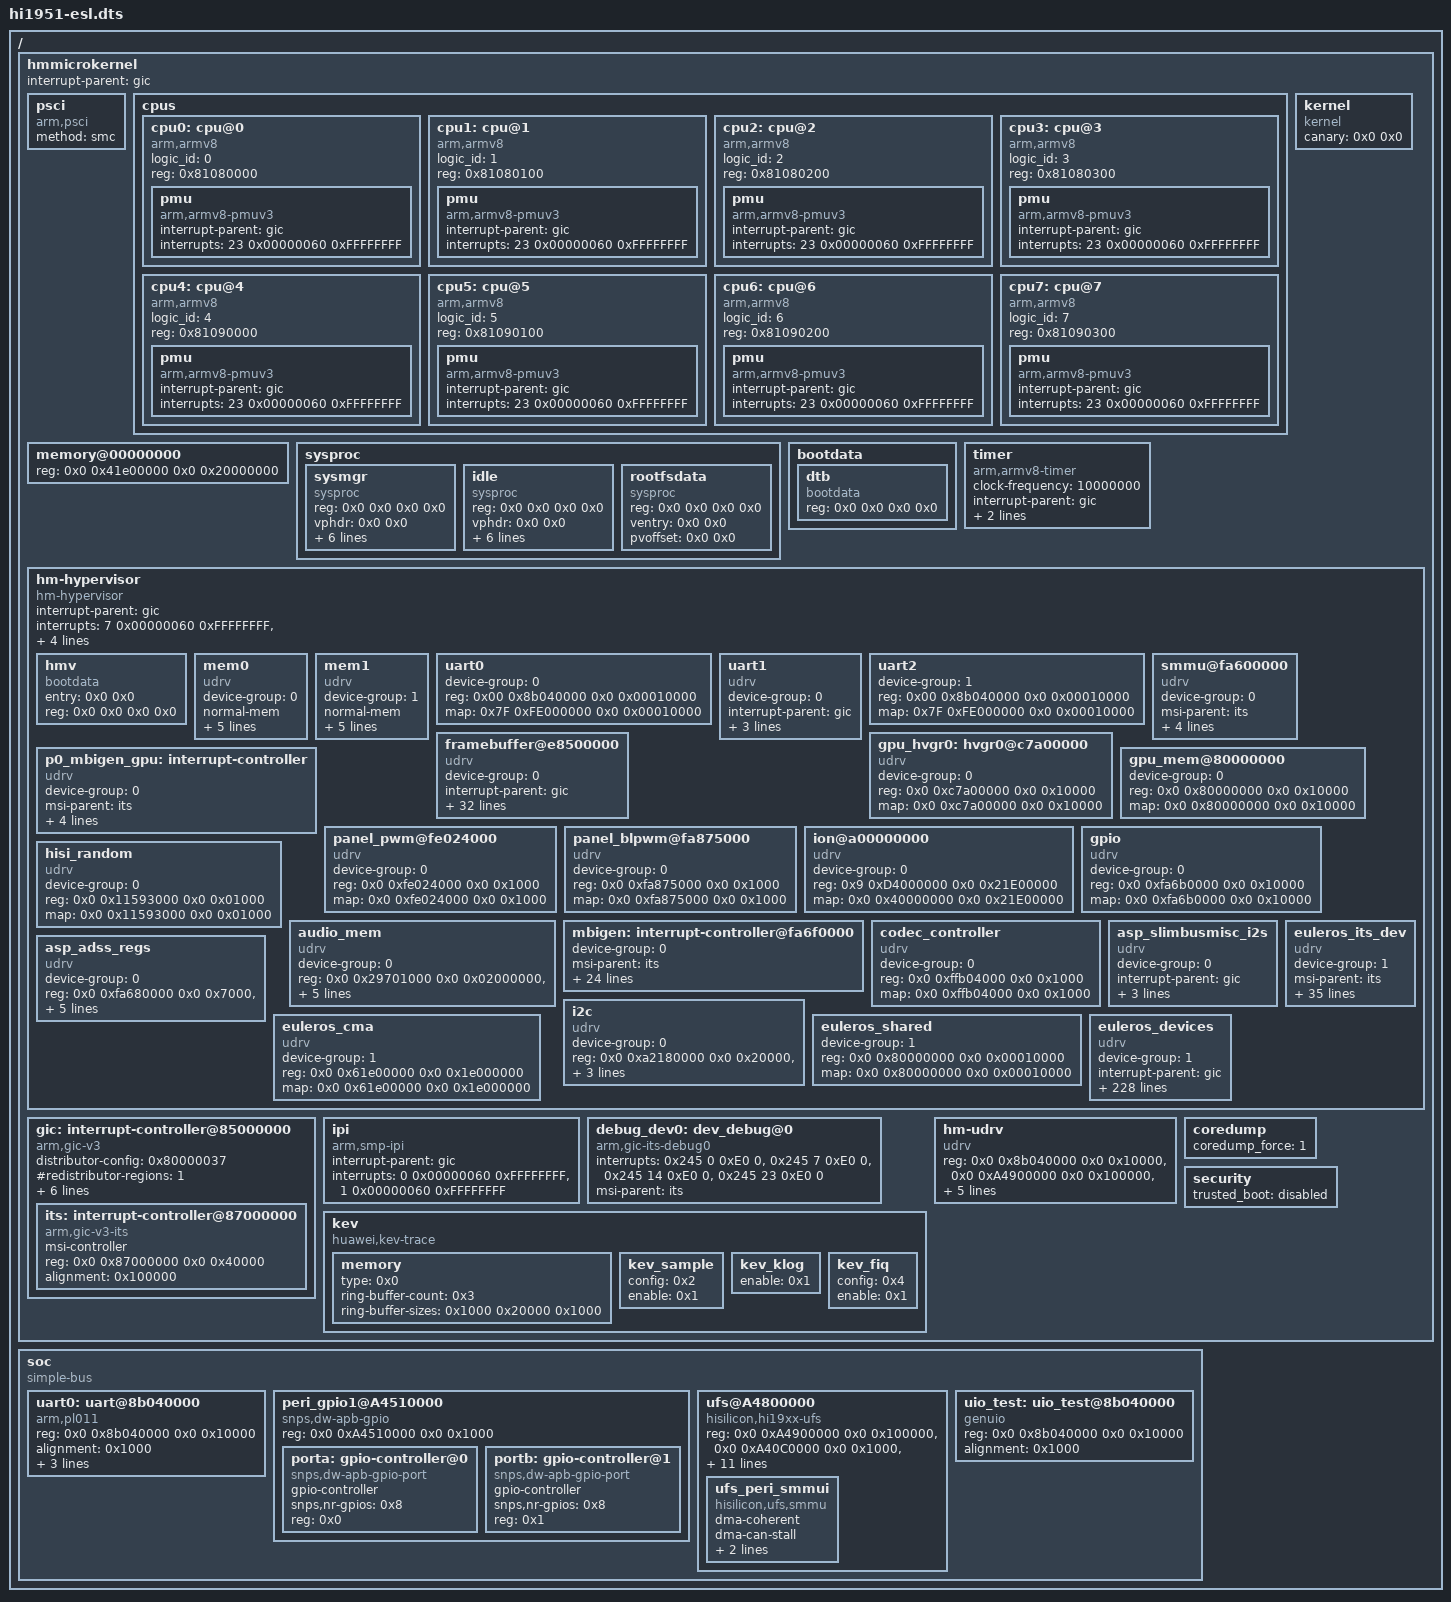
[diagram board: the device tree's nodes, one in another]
/dts-v1/;
/ { #address-cells = <2>; #size-cells = <2>; hmmicrokernel {
	interrupt-parent = <&gic>;
	#address-cells = <2>;
	#size-cells = <2>;

	psci {
		compatible = "arm,psci";
		method = "smc";
	};

	cpus {
		#address-cells = <1>;
		#size-cells = <0>;
		cpu0: cpu@0 {
			compatible = "arm,armv8";
			device_type = "cpu";
			logic_id = <0>;
			reg = <0x81080000>;
			pmu {
				compatible = "arm,armv8-pmuv3";
				interrupt-parent = <&gic>;
				/* PPI 23: PMUIRQ, level triggered, hwprio:0x60 */
				interrupts = <23 0x00000060 0xFFFFFFFF>;
			};
		};

		cpu1: cpu@1 {
			compatible = "arm,armv8";
			device_type = "cpu";
			logic_id = <1>;
			reg = <0x81080100>;
			pmu {
				compatible = "arm,armv8-pmuv3";
				interrupt-parent = <&gic>;
				/* PPI 23: PMUIRQ, level triggered, hwprio:0x60 */
				interrupts = <23 0x00000060 0xFFFFFFFF>;
			};
		};

		cpu2: cpu@2 {
			compatible = "arm,armv8";
			device_type = "cpu";
			logic_id = <2>;
			reg = <0x81080200>;
			pmu {
				compatible = "arm,armv8-pmuv3";
				interrupt-parent = <&gic>;
				/* PPI 23: PMUIRQ, level triggered, hwprio:0x60 */
				interrupts = <23 0x00000060 0xFFFFFFFF>;
			};
		};

		cpu3: cpu@3 {
			compatible = "arm,armv8";
			device_type = "cpu";
			logic_id = <3>;
			reg = <0x81080300>;
			pmu {
				compatible = "arm,armv8-pmuv3";
				interrupt-parent = <&gic>;
				/* PPI 23: PMUIRQ, level triggered, hwprio:0x60 */
				interrupts = <23 0x00000060 0xFFFFFFFF>;
			};
		};

		cpu4: cpu@4 {
			compatible = "arm,armv8";
			device_type = "cpu";
			logic_id = <4>;
			reg = <0x81090000>;
			pmu {
				compatible = "arm,armv8-pmuv3";
				interrupt-parent = <&gic>;
				/* PPI 23: PMUIRQ, level triggered, hwprio:0x60 */
				interrupts = <23 0x00000060 0xFFFFFFFF>;
			};
		};

		cpu5: cpu@5 {
			compatible = "arm,armv8";
			device_type = "cpu";
			logic_id = <5>;
			reg = <0x81090100>;
			pmu {
				compatible = "arm,armv8-pmuv3";
				interrupt-parent = <&gic>;
				/* PPI 23: PMUIRQ, level triggered, hwprio:0x60 */
				interrupts = <23 0x00000060 0xFFFFFFFF>;
			};
		};

		cpu6: cpu@6 {
			compatible = "arm,armv8";
			device_type = "cpu";
			logic_id = <6>;
			reg = <0x81090200>;
			pmu {
				compatible = "arm,armv8-pmuv3";
				interrupt-parent = <&gic>;
				/* PPI 23: PMUIRQ, level triggered, hwprio:0x60 */
				interrupts = <23 0x00000060 0xFFFFFFFF>;
			};
		};

		cpu7: cpu@7 {
			compatible = "arm,armv8";
			device_type = "cpu";
			logic_id = <7>;
			reg = <0x81090300>;
			pmu {
				compatible = "arm,armv8-pmuv3";
				interrupt-parent = <&gic>;
				/* PPI 23: PMUIRQ, level triggered, hwprio:0x60 */
				interrupts = <23 0x00000060 0xFFFFFFFF>;
			};
		};
	};

	memory@00000000 {
		device_type = "memory";
		reg = <0x0 0x41e00000 0x0 0x20000000>;
	};

	sysproc {
		#address-cells = <2>;
		#size-cells = <2>;
		sysmgr {
			compatible = "sysproc", "sysmgr";
			/* filled by bootloader */
			reg      = <0x0 0x0 0x0 0x0>;
			vphdr    = <0x0 0x0>;
			ventry   = <0x0 0x0>;
			pvoffset = <0x0 0x0>;
			nphdrs   = <0>;
			stack_start = <0x0 0x0>;
			stack_end = <0x0 0x0>;
			canary = <0x0 0x0>;
		};
		idle {
			compatible = "sysproc", "idle";
			/* filled by bootloader */
			reg      = <0x0 0x0 0x0 0x0>;
			vphdr    = <0x0 0x0>;
			ventry   = <0x0 0x0>;
			pvoffset = <0x0 0x0>;
			nphdrs   = <0>;
			stack_start = <0x0 0x0>;
			stack_end = <0x0 0x0>;
			canary = <0x0 0x0>;
		};
		rootfsdata {
			compatible = "sysproc", "rootfs";
			/* filled by bootloader */
			reg      = <0x0 0x0 0x0 0x0>;
			ventry   = <0x0 0x0>;
			pvoffset = <0x0 0x0>;
		};

	};

	kernel {
		compatible = "kernel";
		/* filled by bootloader */
		canary = <0x0 0x0>;
	};

	bootdata {
		#address-cells = <2>;
		#size-cells = <2>;
		dtb {
			compatible = "bootdata", "dtb";
			/* filled by bootloader */
			reg = <0x0 0x0 0x0 0x0>;
		};
	};

	timer {
		compatible = "arm,armv8-timer";
		clock-frequency = <10000000>;
		/* interrupt settings */
		interrupt-parent = <&gic>;

		/* PPI 30: Non-secure physical timer
		 * level triggered, only cpu0, hwprio:0x60 */
		interrupts = <30 0x00000060 0xFFFFFFFF>,
			     <26 0x00000060 0xFFFFFFFF>;
	};

	hm-hypervisor {
		compatible = "hm-hypervisor";
		#address-cells = <2>;
		#size-cells = <2>;

		interrupt-parent = <&gic>;
		interrupts = < 7 0x00000060 0xFFFFFFFF>,
			     <25 0x00000060 0xFFFFFFFF>,
			     <27 0x00000060 0xFFFFFFFF>;

		virtual-timer-irq = <27>;
		vgic-base-address = <0x7F 0xFF000000>;

		hmv {
			compatible = "bootdata";
			/* filled by bootloader */
			entry = <0x0 0x0>;
			reg = <0x0 0x0 0x0 0x0>;
		};

		mem0 {
			device-group = <0>;
			compatible = "udrv";
			normal-mem;
			uvmm-access;
			reg = <0x8 0x80000000 0x0 0x0FFF0000>,
			      <0x8 0x90000000 0x0 0x70000000>;
			map = <0x0 0x00000000 0x0 0x0FFF0000>,
			      <0x8 0x90000000 0x0 0x70000000>;
		};

		mem1 {
			device-group = <1>;
			compatible = "udrv";
			normal-mem;
			uvmm-access;
			reg = <0x9 0x00000000 0x0 0x0FFF0000>,
			      <0x9 0x10000000 0x0 0xB0000000>;
			map = <0x9 0x00000000 0x0 0x0FFF0000>,
			      <0x9 0x10000000 0x0 0xB0000000>;
		};

		uart0 {
			device-group = <0>;
			reg = <0x00 0x8b040000 0x0 0x00010000>;
			map = <0x7F 0xFE000000 0x0 0x00010000>;
		};

		uart1 {
			device-group = <0>;
			compatible = "udrv";
			interrupt-parent = <&gic>;
			interrupts = <359 0x000000E0 0xFFFFFFFF>;
			reg = <0x00 0x840c0000 0x0 0x00010000>;
			map = <0x7F 0xFE010000 0x0 0x00010000>;
		};

		uart2 {
			device-group = <1>;
			reg = <0x00 0x8b040000 0x0 0x00010000>;
			map = <0x7F 0xFE000000 0x0 0x00010000>;
		};

		smmu@fa600000 {
			device-group = <0>;
			compatible = "udrv";
			msi-parent = <&its>;
			interrupts = <0x7f41 0 0xE0 0>,
				     <0x7f41 1 0xE0 0>,
				     <0x7f41 2 0xE0 0>,
				     <0x7f41 3 0xE0 0>;
			reg = <0x0 0xfa600000 0x0 0x40000>;
			map = <0x0 0xfa600000 0x0 0x40000>;
		};

		framebuffer@e8500000 {
			device-group = <0>;
			compatible = "udrv";
			interrupt-parent = <&gic>;
			interrupts = <277 0x000000E0 0xFFFFFFFF>,
				     <278 0x000000E0 0xFFFFFFFF>,
				     <279 0x000000E0 0xFFFFFFFF>,
				     <283 0x000000E0 0xFFFFFFFF>,
				     <284 0x000000E0 0xFFFFFFFF>,
				     <363 0x000000E0 0xFFFFFFFF>,
				     <319 0x000000E0 0xFFFFFFFF>,
				     <388 0x000000E0 0xFFFFFFFF>;
			reg = <0x0 0xe8500000 0x0 0x000a0000>,
			      <0x0 0xe8601000 0x0 0x00001000>,
			      <0x0 0xe8680000 0x0 0x00010000>,
			      <0x0 0xe8820000 0x0 0x00001000>,
			      <0x0 0xf8481000 0x0 0x00001000>,
			      <0x0 0xf8500000 0x0 0x00080000>,
			      <0x0 0xf8581000 0x0 0x00001000>,
			      <0x0 0xfa700000 0x0 0x00100000>,
			      <0x0 0xfa89b000 0x0 0x00001000>,
			      <0x0 0xffa2e000 0x0 0x00001000>,
			      <0x0 0xfff01000 0x0 0x00001000>,
			      <0x0 0xfff05000 0x0 0x00001000>;
			map = <0x0 0xe8500000 0x0 0x000a0000>,
			      <0x0 0xe8601000 0x0 0x00001000>,
			      <0x0 0xe8680000 0x0 0x00010000>,
			      <0x0 0xe8820000 0x0 0x00001000>,
			      <0x0 0xf8481000 0x0 0x00001000>,
			      <0x0 0xf8500000 0x0 0x00080000>,
			      <0x0 0xf8581000 0x0 0x00001000>,
			      <0x0 0xfa700000 0x0 0x00100000>,
			      <0x0 0xfa89b000 0x0 0x00001000>,
			      <0x0 0xffa2e000 0x0 0x00001000>,
			      <0x0 0xfff01000 0x0 0x00001000>,
			      <0x0 0xfff05000 0x0 0x00001000>;
		};

		p0_mbigen_gpu: interrupt-controller {
			device-group = <0>;
			compatible = "udrv";
			msi-parent = <&its>;
			interrupts = <0x7f94 0 0xE0 0>,
				     <0x7f94 1 0xE0 0>,
				     <0x7f94 2 0xE0 0>,
				     <0x7f94 3 0xE0 0>;
			reg = <0x0 0xc7800000 0x0 0x100000>;
			map = <0x0 0xc7800000 0x0 0x100000>;
		};

		gpu_hvgr0: hvgr0@c7a00000 {
			device-group = <0>;
			compatible = "udrv";
			reg = <0x0 0xc7a00000 0x0 0x10000>;
			map = <0x0 0xc7a00000 0x0 0x10000>;
		};

		gpu_mem@80000000 {
			device-group = <0>;
			reg = <0x0 0x80000000 0x0 0x10000>;
			map = <0x0 0x80000000 0x0 0x10000>;
		};

		panel_pwm@fe024000 {
			device-group = <0>;
			compatible = "udrv";
			reg = <0x0 0xfe024000 0x0 0x1000>;
			map = <0x0 0xfe024000 0x0 0x1000>;
		};

		panel_blpwm@fa875000 {
			device-group = <0>;
			compatible = "udrv";
			reg = <0x0 0xfa875000 0x0 0x1000>;
			map = <0x0 0xfa875000 0x0 0x1000>;
		};

		ion@a00000000 {
			device-group = <0>;
			compatible = "udrv";
			reg = <0x9 0xD4000000 0x0 0x21E00000>;
			map = <0x0 0x40000000 0x0 0x21E00000>;
		};

		gpio {
			device-group = <0>;
			compatible = "udrv";
			reg = <0x0 0xfa6b0000 0x0 0x10000>;
			map = <0x0 0xfa6b0000 0x0 0x10000>;
		};

		hisi_random {
			device-group = <0>;
			compatible = "udrv";
			reg = <0x0 0x11593000 0x0 0x01000>;
			map = <0x0 0x11593000 0x0 0x01000>;
		};

		audio_mem: audio_mem {
			device-group = <0>;
			compatible = "udrv";
			reg = <0x0 0x29701000 0x0 0x02000000>,
			      <0x9 0xC0000000 0x0 0x10000000>,
			      <0x9 0xD0000000 0x0 0x04000000>;
			map = <0x0 0x29701000 0x0 0x02000000>,
			      <0x0 0x61E00000 0x0 0x10000000>,
			      <0x0 0x71E00000 0x0 0x04000000>;
		};

		mbigen: interrupt-controller@fa6f0000 {
			device-group = <0>;
			msi-parent = <&its>;
			interrupts = <0x7f83 0 0xE0 0>, <0x7f83 1 0xE0 0>,
				     <0x7f90 0 0xE0 0>, <0x7f90 1 0xE0 0>,
				     <0x7f90 2 0xE0 0>, <0x7f90 3 0xE0 0>,
				     <0x7f90 4 0xE0 0>, <0x7f90 5 0xE0 0>,
				     <0x7f90 6 0xE0 0>, <0x7f90 7 0xE0 0>,
				     <0x7f90 8 0xE0 0>, <0x7f90 9 0xE0 0>,
				     <0x7f90 10 0xE0 0>, <0x7f90 11 0xE0 0>,
				     <0x7f90 12 0xE0 0>, <0x7f90 13 0xE0 0>,
				     <0x7f90 14 0xE0 0>, <0x7f90 15 0xE0 0>,
				     <0x7f90 16 0xE0 0>, <0x7f90 17 0xE0 0>,
				     <0x7f90 18 0xE0 0>, <0x7f90 19 0xE0 0>,
				     <0x7f90 20 0xE0 0>, <0x7f90 21 0xE0 0>,
				     <0x7f90 22 0xE0 0>, <0x7f90 23 0xE0 0>,
				     <0x7f90 24 0xE0 0>, <0x7f90 25 0xE0 0>,
				     <0x7f90 26 0xE0 0>, <0x7f90 27 0xE0 0>,
				     <0x7f90 28 0xE0 0>, <0x7f90 29 0xE0 0>,
				     <0x7f90 30 0xE0 0>, <0x7f90 31 0xE0 0>,
				     <0x7f80 0 0xE0 0>, <0x7f80 1 0xE0 0>,
				     <0x7f80 2 0xE0 0>, <0x7f80 3 0xE0 0>,
				     <0x7f80 4 0xE0 0>, <0x7f80 5 0xE0 0>,
				     <0x7f81 0 0xE0 0>, <0x7f81 1 0xE0 0>,
				     <0x7f82 0 0xE0 0>, <0x7f82 1 0xE0 0>;
			reg = <0x0 0xfa6f0000 0x0 0x10000>;
			map = <0x0 0xfa6f0000 0x0 0x10000>;
		};

		codec_controller: codec_controller {
			device-group = <0>;
			compatible = "udrv";
			reg = <0x0 0xffb04000 0x0 0x1000>;
			map = <0x0 0xffb04000 0x0 0x1000>;
		};

		asp_slimbusmisc_i2s: asp_slimbusmisc_i2s {
			device-group = <0>;
			compatible = "udrv";
			interrupt-parent = <&gic>;
			interrupts = <182 0x000000E0 0xFFFFFFFF>;
			reg = <0x0 0xfa400000 0x0 0x1c0000>;
			map = <0x0 0xfa400000 0x0 0x1c0000>;
		};

		asp_adss_regs: asp_adss_regs {
			device-group = <0>;
			compatible = "udrv";
			reg = <0x0 0xfa680000 0x0 0x7000>,
			      <0x0 0xfa6c0000 0x0 0x10000>,
			      <0x0 0xfa660000 0x0 0x4000>;
			map = <0x0 0xfa680000 0x0 0x7000>,
			      <0x0 0xfa6c0000 0x0 0x10000>,
			      <0x0 0xfa660000 0x0 0x4000>;
		};

		i2c {
			device-group = <0>;
			compatible = "udrv";
			reg = <0x0 0xa2180000 0x0 0x20000>,
			      <0x0 0xa20c0000 0x0 0x10000>;
			map = <0x0 0xa2180000 0x0 0x20000>,
			      <0x0 0xa20c0000 0x0 0x10000>;
		};

		euleros_cma {
			device-group = <1>;
			compatible = "udrv";
			reg = <0x0 0x61e00000 0x0 0x1e000000>;
			map = <0x0 0x61e00000 0x0 0x1e000000>;
		};

		euleros_shared {
			device-group = <1>;
			reg = <0x0 0x80000000 0x0 0x00010000>; //rdr_ap_adapter rdr_spmi mttcan2 mttcan3 mttcan4
			map = <0x0 0x80000000 0x0 0x00010000>; //rdr_ap_adapter rdr_spmi mttcan2 mttcan3 mttcan4
		};

		euleros_its_dev {
			device-group = <1>;
			compatible = "udrv";
			msi-parent = <&its>;

			interrupts =	<0x7b00 0x00 0xE0 0>,//pcie dma
					<0x7b00 0x01 0xE0 0>,//pcie dma
					<0x7b00 0x02 0xE0 0>,//pcie dma
					<0x7b00 0x03 0xE0 0>,//pcie dma
					<0x7b00 0x1f 0xE0 0>,//pcie dma
					<0x7b08 0x00 0xE0 0>,//doorbell
					<0x7b08 0x0b 0xE0 0>,//doorbell
					<0x7b08 0x0c 0xE0 0>,//doorbell
					<0x7b08 0x0d 0xE0 0>,//doorbell
					<0x7b08 0x0e 0xE0 0>,//doorbell
					<0x7b08 0x0f 0xE0 0>,//doorbell
					<0x7b08 0x10 0xE0 0>,//doorbell
					<0x7b08 0x11 0xE0 0>,//doorbell
					<0x7b08 0x12 0xE0 0>,//doorbell
					<0x7b08 0x15 0xE0 0>,//doorbell
					<0x7b08 0x16 0xE0 0>,//doorbell
					<0x7b08 0x17 0xE0 0>,//doorbell
					<0x7b08 0x18 0xE0 0>,//doorbell
					<0x7b08 0x19 0xE0 0>,//doorbell
					<0x7b08 0x1a 0xE0 0>,//doorbell
					<0x7b08 0x1b 0xE0 0>,//doorbell
					<0x7b08 0x1c 0xE0 0>,//doorbell
					<0x7f1b 0x00 0xE0 0>,//mmu
					<0x7f1b 0xff 0xE0 0>,//mmu
					<0x7f20 0x00 0xE0 0>,//peri_smmu
					<0x7f20 0x01 0xE0 0>,//dvpp
					<0x7f21 0x00 0xE0 0>,//dvpp
					<0x7f21 0x01 0xE0 0>,//dvpp
					<0x7f22 0x00 0xE0 0>,//dvpp
					<0x7f22 0x01 0xE0 0>,//dvpp
					<0x7f23 0x00 0xE0 0>,//dvpp/dsmmu0
					<0x7f23 0x01 0xE0 0>,//dvpp/dsmmu0
					<0x7f24 0x00 0xE0 0>,//dvpp
					<0x7f24 0x01 0xE0 0>,//dvpp
					<0x7f25 0x00 0xE0 0>,//dvpp
					<0x7f25 0x01 0xE0 0>,//dvpp
					<0x7f26 0x00 0xE0 0>,//mmu
					<0x7f26 0x01 0xE0 0>,//mmu
					<0x7f27 0x00 0xE0 0>,//mmu
					<0x7f27 0x01 0xE0 0>,//mmu
					<0x7f28 0x00 0xE0 0>,//mmu
					<0x7f28 0x01 0xE0 0>,//mmu
					<0x7f31 0x00 0xE0 0>,//mmu
					<0x7f31 0x01 0xE0 0>,//mmu
					<0x7f45 0x00 0xE0 0>,//mmu
					<0x7f45 0xff 0xE0 0>,//mmu
					<0x7f46 0x00 0xE0 0>,//mmu
					<0x7f46 0x01 0xE0 0>,//mmu
					<0x7f49 0x00 0xE0 0>,//dvpp_smmu0
					<0x7f49 0x01 0xE0 0>,//dvpp_smmu0
					<0x7f58 0x00 0xE0 0>,//mbigen_vdec
					<0x7f58 0xff 0xE0 0>,//mbigen_vdec
					<0x7f5d 0x00 0xE0 0>,//mbigen_jpegd
					<0x7f5d 0xff 0xE0 0>,//mbigen_jpegd
					<0x7f5f 0x00 0xE0 0>,//mbigen_jpege
					<0x7f5f 0xff 0xE0 0>,//mbigen_jpege
					<0x7f77 0x00 0xE0 0>,//mbigen_vpc_err
					<0x7f77 0xff 0xE0 0>,//mbigen_vpc_err
					<0x7f91 0xff 0xE0 0>,//dvpp
					<0x7fe4 0xff 0xE0 0>;//p0_mbigen_io

			reg =	<0x2 0x01080000 0x0 0x00010000>, //drv_pcie
				<0x0 0xc6f10000 0x0 0x00010000>; //drv_pcie
			map =	<0x2 0x01080000 0x0 0x00010000>, //drv_pcie
				<0x0 0xc6f10000 0x0 0x00010000>; //drv_pcie
		};

		euleros_devices {
			device-group = <1>;
			compatible = "udrv";
			interrupt-parent = <&gic>;

			reg =	<0xA 0xdf800000 0x0 0x00800000>, //l2buffer
				<0x1 0x100C0000 0x0 0x00010000>, //mntn rdr & devdrv
				<0x1 0x02060000 0x0 0x00010000>, //devdrv Dispatch
				<0x1 0x000E0000 0x0 0x00010000>, //devdrv FW
				<0x1 0x000a0000 0x0 0x00010000>, //dvpp & devdrv MN

				<0x0 0xd7b00000 0x0 0x00100000>, //pcie
				<0x0 0xd7d00000 0x0 0x00100000>, //pcie
				<0x0 0xcf090000 0x0 0x0000B000>, //ipc0
				<0x0 0xcaa00000 0x0 0x00080000>, //dvpp vpc2 vpc3
				<0x0 0xca800000 0x0 0x00060000>, //dvpp dsmmu5 dvpp_controler dispatch
				<0x0 0xca200000 0x0 0x00080000>, //dvpp vpc0 vpc1
				<0x0 0xca0c0000 0x0 0x00010000>, //dvpp dvpp_controler
				<0x0 0xca000000 0x0 0x00070000>, //dvpp dsmmu4 dvpp_controler dispatch
				<0x0 0xc9a00000 0x0 0x00080000>, //dvpp vpc2 vpc3
				<0x0 0xc9800000 0x0 0x00060000>, //dvpp dsmmu3 dvpp_controler
				<0x0 0xc9400000 0x0 0x00100000>, //venc0
				<0x0 0xc9200000 0x0 0x00080000>, //dvpp vpc0 vpc1
				<0x0 0xc9000000 0x0 0x00150000>, //dvpp dsmmu2 dvpp_controler dispatch / dsmmu0 dvpp_controller
				<0x0 0xc92c0000 0x0 0x00010000>, //jpege0
				<0x0 0xc9180000 0x0 0x00060000>, //vdec0 vpc0 vpc-err
				<0x0 0xc8a00000 0x0 0x00080000>, //dvpp vpc2 vpc3
				<0x0 0xc8800000 0x0 0x00060000>, //dvpp dsmmu1 dvpp_controler
				<0x0 0xc8200000 0x0 0x00080000>, //dvpp vpc0 vpc1
				<0x0 0xc8000000 0x0 0x000d0000>, //dvpp dsmmu0 dvpp_controler dispatch
				<0x0 0xc2300000 0x0 0x00040000>, //smmu smmu_ai1
				<0x0 0xc2100000 0x0 0x00040000>, //smmu smmu_ai0
				<0x0 0xc1100000 0x0 0x00040000>, //smmu smmu_aive0
				<0x0 0xbb000000 0x0 0x00040000>,
				<0x0 0xbac00000 0x0 0x00400000>, //ts0_doorbell_paddr
				<0x0 0xba700000 0x0 0x00100000>,
				<0x0 0xba400000 0x0 0x00100000>, //ts0_sram_paddr
				<0x0 0xba060000 0x0 0x00050000>, //drv_devmng ts0_sysctl ipc2
				<0x0 0xb9c00000 0x0 0x00400000>, //ts1_doorbell_paddr
				<0x0 0xb9700000 0x0 0x00100000>,
				<0x0 0xb9400000 0x0 0x00020000>, //ts1_sram_paddr
				<0x0 0xb9060000 0x0 0x00050000>, // devdrv tsl_sysctl ipc3
				<0x0 0xa4070000 0x0 0x00010000>, //virtio
				<0x0 0xa4000000 0x0 0x00040000>, //peri_smmu_controller1
				<0x0 0xa3000000 0x0 0x00800000>, //eth1 eth2
				<0x0 0xa2500000 0x0 0x00a00000>, //pcie
				<0x0 0xa2240000 0x0 0x00002000>, //eth1 eth2
				<0x0 0xa20f0000 0x0 0x00010000>, //p0_mbigen_io
				<0x0 0xa20c0000 0x0 0x00008000>, //eth1 eth2
				<0x0 0xab730000 0x0 0x0000b000>, //ipc7
				<0x0 0xab330000 0x0 0x0000b000>, //ipc6
				<0x0 0xa9730000 0x0 0x0000b000>, //ipc5
				<0x0 0xa9330000 0x0 0x0000b000>, //ipc4
				<0x0 0xa6022000 0x0 0x00001000>, //sensorhub
				<0x0 0xa4500000 0x0 0x00010000>, //mttcan2 mttcan3 mttcan4: before ufs sysctl
				<0x0 0xa4511000 0x0 0x001ef000>, //mttcan2 mttcan3 mttcan4: after ufs sysctl
				<0x0 0x88000000 0x0 0x00040000>, //svm smmu_hac
				<0x0 0x84870000 0x0 0x0000B000>, //ipc1
				<0x0 0x80100000 0x0 0x00001000>, //ethernet mdio
				<0x0 0x80010000 0x0 0x00010000>, //devdrv SYSCTL
				<0x0 0x2f900000 0x0 0x01e00000>, //blackbox_reserved rdr rdr_ddrdump_index rdr_lpm3_sram
				<0x0 0x2BF80000 0x0 0x00100000>,
				<0x0 0x2BD00000 0x0 0x00100000>, //profdrv test
				<0x0 0x2bb80000 0x0 0x00100000>, //runtime test
				<0x0 0x2B981000 0x0 0x00030000>, //cq_uio_mem
				<0x0 0x29502000 0x0 0x001FF000>, //log_redirect
				<0x0 0x29500000 0x0 0x00001000>, //aicpu mailbox
				<0x0 0x27200000 0x0 0x00100000>, //hlt profdrv test
				<0x0 0x26d00000 0x0 0x00100000>, //hlt profdrv test

				<0x0 0x0fb00000 0x0 0x01a93000>, //tsfw before random
				<0x0 0x11594000 0x0 0x1576c000>, //tsfw after random
				<0x0 0x0bb00000 0x0 0x04000000>, //devdrv sqcq
				<0x0 0x0B280000 0x0 0x00001000>, //mntn rdr
				<0x0 0x0B200000 0x0 0x00001000>, //mntn rdr
				<0x0 0x0AE00000 0x0 0x00006000>, //mntn rdr
				<0x0 0x0A400000 0x0 0x00A00000>, //mntn rdr
				<0x0 0x00A20000 0x0 0x00001000>, //tsensor_shm_paddr
				<0x0 0x009fe000 0x0 0x00003000>, //svm davinci_svm & aicpu / aicpufw_config_reserved davinci_svm
				<0x0 0x00000000 0x0 0x00900000>; //pcie

			map =	<0xA 0xdf800000 0x0 0x00800000>, //l2buffer
				<0x1 0x100C0000 0x0 0x00010000>, //mntn rdr & devdrv
				<0x1 0x02060000 0x0 0x00010000>, //devdrv Dispatch
				<0x1 0x000E0000 0x0 0x00010000>, //devdrv FW
				<0x1 0x000a0000 0x0 0x00010000>, //dvpp & devdrv MN

				<0x0 0xd7b00000 0x0 0x00100000>, //pcie
				<0x0 0xd7d00000 0x0 0x00100000>, //pcie
				<0x0 0xcf090000 0x0 0x0000B000>, //ipc0
				<0x0 0xcaa00000 0x0 0x00080000>, //dvpp vpc2 vpc3
				<0x0 0xca800000 0x0 0x00060000>, //dvpp dsmmu5 dvpp_controler dispatch
				<0x0 0xca200000 0x0 0x00080000>, //dvpp vpc0 vpc1
				<0x0 0xca0c0000 0x0 0x00010000>, //dvpp dvpp_controler
				<0x0 0xca000000 0x0 0x00070000>, //dvpp dsmmu4 dvpp_controler dispatch
				<0x0 0xc9a00000 0x0 0x00080000>, //dvpp vpc2 vpc3
				<0x0 0xc9800000 0x0 0x00060000>, //dvpp dsmmu3 dvpp_controler
				<0x0 0xc9400000 0x0 0x00100000>, //venc0
				<0x0 0xc9200000 0x0 0x00080000>, //dvpp vpc0 vpc1
				<0x0 0xc9000000 0x0 0x00150000>, //dvpp dsmmu2 dvpp_controler dispatch / dsmmu0 dvpp_controller
				<0x0 0xc92c0000 0x0 0x00010000>, //jpege0
				<0x0 0xc9180000 0x0 0x00060000>, //vdec0 vpc0 vpc-err
				<0x0 0xc8a00000 0x0 0x00080000>, //dvpp vpc2 vpc3
				<0x0 0xc8800000 0x0 0x00060000>, //dvpp dsmmu1 dvpp_controler
				<0x0 0xc8200000 0x0 0x00080000>, //dvpp vpc0 vpc1
				<0x0 0xc8000000 0x0 0x000d0000>, //dvpp dsmmu0 dvpp_controler dispatch
				<0x0 0xc2300000 0x0 0x00040000>, //smmu smmu_ai1
				<0x0 0xc2100000 0x0 0x00040000>, //smmu smmu_ai0
				<0x0 0xc1100000 0x0 0x00040000>, //smmu smmu_aive0
				<0x0 0xbb000000 0x0 0x00040000>,
				<0x0 0xbac00000 0x0 0x00400000>, //ts0_doorbell_paddr
				<0x0 0xba700000 0x0 0x00100000>,
				<0x0 0xba400000 0x0 0x00100000>, //ts0_sram_paddr
				<0x0 0xba060000 0x0 0x00050000>, //drv_devmng ts0_sysctl ipc2
				<0x0 0xb9c00000 0x0 0x00400000>, //ts1_doorbell_paddr
				<0x0 0xb9700000 0x0 0x00100000>,
				<0x0 0xb9400000 0x0 0x00020000>, //ts1_sram_paddr
				<0x0 0xb9060000 0x0 0x00050000>, // devdrv tsl_sysctl ipc3
				<0x0 0xa4070000 0x0 0x00010000>, //virtio
				<0x0 0xa4000000 0x0 0x00040000>, //peri_smmu_controller1
				<0x0 0xa3000000 0x0 0x00800000>, //eth1 eth2
				<0x0 0xa2500000 0x0 0x00a00000>, //pcie
				<0x0 0xa2240000 0x0 0x00002000>, //eth1 eth2
				<0x0 0xa20f0000 0x0 0x00010000>, //p0_mbigen_io
				<0x0 0xa20c0000 0x0 0x00008000>, //eth1 eth2
				<0x0 0xab730000 0x0 0x0000b000>, //ipc7
				<0x0 0xab330000 0x0 0x0000b000>, //ipc6
				<0x0 0xa9730000 0x0 0x0000b000>, //ipc5
				<0x0 0xa9330000 0x0 0x0000b000>, //ipc4
				<0x0 0xa6022000 0x0 0x00001000>, //sensorhub
				<0x0 0xa4500000 0x0 0x00010000>, //mttcan2 mttcan3 mttcan4: before ufs sysctl
				<0x0 0xa4511000 0x0 0x001ef000>, //mttcan2 mttcan3 mttcan4: after ufs sysctl
				<0x0 0x88000000 0x0 0x00040000>, //svm smmu_hac
				<0x0 0x84870000 0x0 0x0000B000>, //ipc1
				<0x0 0x80100000 0x0 0x00001000>, //ethernet mdio
				<0x0 0x80010000 0x0 0x00010000>, //devdrv SYSCTL
				<0x0 0x2f900000 0x0 0x01e00000>, //blackbox_reserved rdr rdr_ddrdump_index rdr_lpm3_sram
				<0x0 0x2BF80000 0x0 0x00100000>,
				<0x0 0x2BD00000 0x0 0x00100000>, //profdrv test
				<0x0 0x2bb80000 0x0 0x00100000>, //runtime test
				<0x0 0x2B981000 0x0 0x00030000>, //cq_uio_mem
				<0x0 0x29502000 0x0 0x001FF000>, //log_redirect
				<0x0 0x29500000 0x0 0x00001000>, //aicpu mailbox
				<0x0 0x27200000 0x0 0x00100000>, //hlt profdrv test
				<0x0 0x26d00000 0x0 0x00100000>, //hlt profdrv test

				<0x0 0x0fb00000 0x0 0x01a93000>, //tsfw before random
				<0x0 0x11594000 0x0 0x1576c000>, //tsfw after random
				<0x0 0x0bb00000 0x0 0x04000000>, //devdrv sqcq
				<0x0 0x0B280000 0x0 0x00001000>, //mntn rdr
				<0x0 0x0B200000 0x0 0x00001000>, //mntn rdr
				<0x0 0x0AE00000 0x0 0x00006000>, //mntn rdr
				<0x0 0x0A400000 0x0 0x00A00000>, //mntn rdr
				<0x0 0x00A20000 0x0 0x00001000>, //tsensor_shm_paddr
				<0x0 0x009fe000 0x0 0x00003000>, //svm davinci_svm & aicpu / aicpufw_config_reserved davinci_svm
				<0x0 0x00000000 0x0 0x00900000>; //pcie

			/* interrupt settings:
			 * 1st cell: real hardware irq number
			 * 2nd cell: interrupt config
			 *     bit [27:26]: Group setting
			 *     bit [24]: Trigger Type
			 *     bit [23:8]: Reserved
			 *     bit [7:0]: Priority
			 * 3rd cell: interrupt target config
			 *     Warning: Send to all cpus by default
			 */
			interrupts =	<32  0x010000E0 0xFFFFFFFF>, // llc
					<65  0x000000E0 0xFFFFFFFF>, // vpc
					<67  0x010000E0 0xFFFFFFFF>, // smmu
					<68  0x010000E0 0xFFFFFFFF>, // smmu
					<70  0x000000E0 0xFFFFFFFF>, // dvpp vpc0	<0    38 4>
					<71  0x000000E0 0xFFFFFFFF>, // dvpp vpc1	<0    39 4>
					<72  0x000000E0 0xFFFFFFFF>, // dvpp vpc2	<0    40 4>
					<73  0x000000E0 0xFFFFFFFF>, // dvpp vpc3	<0    41 4>
					<75  0x000000E0 0xFFFFFFFF>, // dvpp vpc0	<0    43 4>
					<76  0x000000E0 0xFFFFFFFF>, // dvpp vpc1	<0    44 4>
					<77  0x000000E0 0xFFFFFFFF>, // dvpp vpc2	<0    45 4>
					<78  0x000000E0 0xFFFFFFFF>, // dvpp vpc3	<0    46 4>
					<79  0x000000E0 0xFFFFFFFF>, // venc0 <0 47 4>
					<80  0x000000E0 0xFFFFFFFF>, // dvpp vpc0	<0    48 4>
					<81  0x000000E0 0xFFFFFFFF>, // dvpp vpc1	<0    49 4>
					<82  0x000000E0 0xFFFFFFFF>, // dvpp vpc2	<0    50 4>
					<83  0x000000E0 0xFFFFFFFF>, // dvpp vpc3	<0    51 4>
					<150 0x000000E0 0xFFFFFFFF>, // virtio		<0  0x76 4>
					<174 0x000000E0 0xFFFFFFFF>,//mttcan2		<0 142 4>
					<175 0x000000E0 0xFFFFFFFF>,//mttcan2		<0 143 4>
					<176 0x000000E0 0xFFFFFFFF>,//mttcan3		<0 144 4>
					<177 0x000000E0 0xFFFFFFFF>,//mttcan3		<0 145 4>
					<178 0x000000E0 0xFFFFFFFF>,//mttcan4	 	<0 146 4>
					<179 0x000000E0 0xFFFFFFFF>,//mttcan4		<0 147 4>
					<195 0x000000E0 0xFFFFFFFF>,//sensorhub		<0 163 4>
					<196 0x000000E0 0xFFFFFFFF>,//sensorhub		<0 164 4>
					<210 0x000000E0 0xFFFFFFFF>,//ipc1 mailbox-0	<0 178 4>
					<211 0x000000E0 0xFFFFFFFF>,//ipc1 mailbox-1	<0 179 4>
					<212 0x000000E0 0xFFFFFFFF>,//ipc1 mailbox-2	<0 180 4>
					<213 0x000000E0 0xFFFFFFFF>,//ipc1 mailbox-3	<0 181 4>
					<221 0x000000E0 0xFFFFFFFF>,//ipc1 ACPU0	<0 189 4>
					<222 0x000000E0 0xFFFFFFFF>,//ipc1 ACPU1	<0 190 4>
					<223 0x000000E0 0xFFFFFFFF>,//ipc1 ACPU2	<0 191 4>
					<224 0x000000E0 0xFFFFFFFF>,//ipc1 ACPU3	<0 192 4>
					<225 0x000000E0 0xFFFFFFFF>,//ipc0 mailbox-0	<0 193 4>
					<226 0x000000E0 0xFFFFFFFF>,//ipc0 ACPU0	<0 194 4>
					<230 0x000000E0 0xFFFFFFFF>,//devdrv ts-1	<0 0xC6 4>
					<234 0x000000E0 0xFFFFFFFF>,//ipc3 ACPU0 mailbox-5	<0 202 4>
					<235 0x000000E0 0xFFFFFFFF>,//ipc3 ACPU1 mailbox-6	<0 203 4>
					<236 0x000000E0 0xFFFFFFFF>,//ipc3 ACPU2 mailbox-7	<0 204 4>
					<237 0x000000E0 0xFFFFFFFF>,//ipc3 ACPU3 mailbox-8	<0 205 4>
					<245 0x000000E0 0xFFFFFFFF>,//aicpudrv 		<0 213 4>
					<247 0x000000E0 0xFFFFFFFF>,//devdrv ts-1	<0 0xD7 4>
					<252 0x000000E0 0xFFFFFFFF>,//devdrv ts-0	<0 0xDC 4>
					<256 0x000000E0 0xFFFFFFFF>,//ipc2 ACPU0 mailbox-5	<0 224 4>
					<257 0x000000E0 0xFFFFFFFF>,//ipc2 ACPU1 mailbox-6	<0 225 4>
					<258 0x000000E0 0xFFFFFFFF>,//ipc2 ACPU2 mailbox-7	<0 226 4>
					<259 0x000000E0 0xFFFFFFFF>,//ipc2 ACPU3 mailbox-8	<0 227 4>
					<267 0x000000E0 0xFFFFFFFF>,//aicpudrv		<0 235 4>
					<269 0x000000E0 0xFFFFFFFF>,//devdrv ts-0	<0 0xED 4>
					<275 0x000000E0 0xFFFFFFFF>,//ethernet		<0 243 4>
					<285 0x000000E0 0xFFFFFFFF>,//platform		<0 253 4>
					<286 0x000000E0 0xFFFFFFFF>,//platform	 	<0 254 4>
					<292 0x000000E0 0xFFFFFFFF>,//ipc0 mailbox-1	<0 260 4>
					<293 0x000000E0 0xFFFFFFFF>,//ipc0 ACPU1	<0 261 4>
					<296 0x000000E0 0xFFFFFFFF>,//ipc0 mailbox-2	<0 264 4>
					<297 0x000000E0 0xFFFFFFFF>,//ipc0 ACPU2	<0 265 4>
					<300 0x000000E0 0xFFFFFFFF>,//trusted_core	<0 268 4>
					<304 0x000000E0 0xFFFFFFFF>,//ipc4 mailbox-0	<0 272 4>
					<305 0x000000E0 0xFFFFFFFF>,//ipc4 mailbox-1	<0 273 4>
					<306 0x000000E0 0xFFFFFFFF>,//ipc4 mailbox-2	<0 274 4>
					<307 0x000000E0 0xFFFFFFFF>,//ipc5 mailbox-0	<0 275 4>
					<308 0x000000E0 0xFFFFFFFF>,//ipc5 mailbox-1	<0 276 4>
					<309 0x000000E0 0xFFFFFFFF>,//ipc5 mailbox-2	<0 277 4>
					<310 0x000000E0 0xFFFFFFFF>,//ipc4 ACPU		<0 278 4>
					<311 0x000000E0 0xFFFFFFFF>,//ipc5 ACPU		<0 279 4>
					<312 0x000000E0 0xFFFFFFFF>,//ipc0 mailbox-3	<0 280 4>
					<313 0x000000E0 0xFFFFFFFF>,//ipc0 ACPU3	<0 281 4>
					<320 0x000000E0 0xFFFFFFFF>,//ipc6 ACPU		<0 288 4>
					<321 0x000000E0 0xFFFFFFFF>,//ipc7 ACPU		<0 289 4>
					<323 0x000000E0 0xFFFFFFFF>,//devdrv ts-0	<0 0x123 4>
					<324 0x000000E0 0xFFFFFFFF>,//devdrv ts-1	<0 0x124 4>
					<331 0x000000E0 0xFFFFFFFF>,//ipc6 mailbox-0	<0 299 4>
					<332 0x000000E0 0xFFFFFFFF>,//ipc6 mailbox-1	<0 300 4>
					<333 0x000000E0 0xFFFFFFFF>,//ipc6 mailbox-2	<0 301 4>
					<334 0x000000E0 0xFFFFFFFF>,//ipc7 mailbox-0	<0 302 4>
					<335 0x000000E0 0xFFFFFFFF>,//ipc7 mailbox-1	<0 303 4>
					<336 0x000000E0 0xFFFFFFFF>,//ipc7 mailbox-2	<0 304 4>
					<401 0x000000E0 0xFFFFFFFF>, // dispatch	<0 0x173 4>
					<402 0x000000E0 0xFFFFFFFF>, // dvpp		<0 0x172 4>
					<403 0x000000E0 0xFFFFFFFF>, // dvpp		<0 0x173 4>
					<404 0x000000E0 0xFFFFFFFF>; // dvpp		<0 0x174 4>
		};
	};

	/* See Documentation/dts-gic.md for interrupts and distributor_config */
	gic: interrupt-controller@85000000 {
		compatible = "arm,gic-v3";

		#address-cells = <2>;
		#size-cells = <2>;

		/* Enable group 0, Group1NS, Group1S, ARE_NS, ARE_S,
		 * Split EOI and Deactive Mode */
		distributor-config = <0x80000037>;

		#interrupt-cells = <3>;
		#redistributor-regions = <1>;
		redistributor-stride = <0x20000>;
		interrupt-controller;

		reg =	<0x0 0x85000000 0x0 0x10000>,	/* GICD */
			<0x0 0x85100000 0x0 0x800000>;	/* GICR */
		alignment = <0x100000 0x100000>;

		interrupts = <25 0x000000E0 0xFFFFFFFF>;

		/* We haven't support this */
		its: interrupt-controller@87000000 {
			compatible = "arm,gic-v3-its";
			msi-controller;
			reg = <0x0 0x87000000 0x0 0x40000>;
			alignment = <0x100000>;
			#interrupt-cells = <4>;
		};
	};

	ipi {
		/* smp ipi */
		compatible = "arm,smp-ipi";

		interrupt-parent = <&gic>;

		interrupts =	<0 0x00000060 0xFFFFFFFF>, /* IPI_RESCHEDULE */
				<1 0x00000060 0xFFFFFFFF>; /* IPI_CALL_FUNC */
	};

	/* used to debug its driver */
	debug_dev0:dev_debug@0 {
		compatible = "arm,gic-its-debug0";
		interrupts =	<0x245 0 0xE0 0>,
				<0x245 7 0xE0 0>,
				<0x245 14 0xE0 0>,
				<0x245 23 0xE0 0>;
		msi-parent = <&its>;
	};

	kev {
		compatible = "huawei,kev-trace";

		memory {
			type = <0x0>;
			ring-buffer-count = <0x3>;
			ring-buffer-sizes = <0x1000 0x20000 0x1000>;
		};
		kev_sample {
			config = <0x2>;
			enable = <0x1>;
		};
		kev_klog {
			enable = <0x1>;
		};
		kev_fiq {
			config = <0x4>;
			enable = <0x1>;
		};
	};

	hm-udrv {
		compatible = "udrv";
		reg = <0x0 0x8b040000 0x0 0x10000>,
		      <0x0 0xA4900000 0x0 0x100000>,
		      <0x0 0xA40C0000 0x0 0x1000>,
		      <0x0 0xA4510000 0x0 0x1000>,
		      <0x0 0xA4800000 0x0 0x100000>,
		      <0x0 0x80000000 0x0 0x10000>,
		      <0x0 0xfa6f0000 0x0 0x10000>;
		};

	coredump {
		coredump_force = <1>;
	};
	security {
		trusted_boot = "disabled";
	};
	};

	soc {
		compatible = "simple-bus";
		#address-cells = <2>;
		#size-cells = <2>;
		ranges;

		uart0: uart@8b040000 {
			compatible = "arm,pl011", "arm,pl011,uart";
			reg = <0x0 0x8b040000 0x0 0x10000>;
			alignment = <0x1000>;

			/* kernel control input */
			kernel-input;

			interrupt-parent=<&gic>;
			interrupts=<349 0x00000060 0x00000001>;
		};

		peri_gpio1@A4510000 {
			compatible = "snps,dw-apb-gpio";
			reg = <0x0 0xA4510000 0x0 0x1000>;
			#address-cells = <0x1>;
			#size-cells = <0x0>;

			porta:gpio-controller@0 {
				compatible = "snps,dw-apb-gpio-port";
				gpio-controller;
				#gpio-cells = <0x2>;
				snps,nr-gpios = <0x8>;
				reg = <0x0>;
				linux,phandle = <0x2>;
				phandle = <0x2>;
			};

			portb:gpio-controller@1 {
				compatible = "snps,dw-apb-gpio-port";
				gpio-controller;
				#gpio-cells = <0x2>;
				snps,nr-gpios = <0x8>;
				reg = <0x1>;
			};
		};

		ufs@A4800000 {
			    compatible = "hisilicon,hi19xx-ufs";
			//  memory-region = <&ufs_test_reserved>;
			    reg = <0x0 0xA4900000 0x0 0x100000>,
			          <0x0 0xA40C0000 0x0 0x1000>,
			          <0x0 0xA4800000 0x0 0x100000>;
			    interrupt-parent = <&gic>;
			    interrupts = <0x0 0x70 0x4>,
					 <0x0 0x6E 0x4>,
					 <0x0 0x6F 0x4>;
			//  ufs-hisi-use-one-lane;
			    ufs-hisi-use-rate-B;
			    ufs-hisi-broken-fastauto;
			    ufs-hisi-use-HS-GEAR1;
			//  ufs-hisi-unipro-scrambing;
			//  ufs-hisi-broken-clk-gate-bypass;
			//  ufs-hisi-use-pm-runtime;
			    ufs-hisi-use-auto-H8;
			//  ufs-hisi-pwm-daemon-intr;
			//  ufs-hisi-dev-tmt-intr;
			//  ufs-hisi-broken-idle-intr;
			//  ufs-hisi-use-clk-gating;
			//  ufs-hisi-use-pwr-gating;
			//  ufs-hisi-use-clk-scaling;
			//  ufs-hisi-use-auto-bkops-suspend;
			    suspend_power_level = <5>;          //DEVICE_POWER_DOWN, UIC_LINK_OFF
			    device-reset-gpio = <&porta 0x0 0x0>;
			    device-refclk-sel = <2>;
			//  ufs-hisi-use-smmu;
			    ufs_peri_smmui {
			        compatible = "hisilicon,ufs,smmu";
			        //iommus = <&peri_smmu 0x7f20>;
			        dma-coherent;
			        dma-can-stall;
			        pasid-bits = <0x10>;
			        pasid-num-bits = <0x10>;
			};
		};

		uio_test: uio_test@8b040000 {
			compatible = "genuio";
			reg = <0x0 0x8b040000 0x0 0x10000>;
			alignment = <0x1000>;
		};
	};
};
